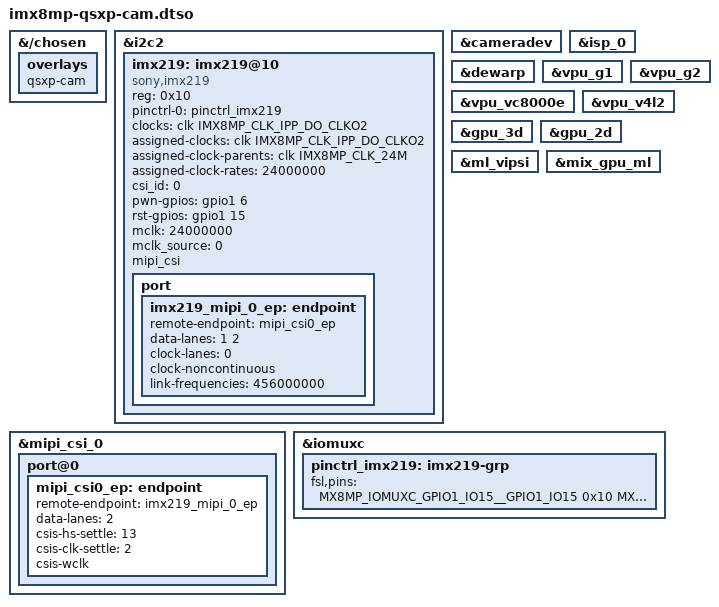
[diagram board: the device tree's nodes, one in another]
// SPDX-License-Identifier: (GPL-2.0 OR MIT)
/*
 * Copyright 2023 Markus Bauer <MB@KARO-electronics.de>
 *
 */

/dts-v1/;
/plugin/;

#include <dt-bindings/clock/imx8mp-clock.h>
#include <dt-bindings/gpio/gpio.h>
#include "imx8mp-pinfunc.h"

&{/chosen} {
	overlays {
		qsxp-cam;
	};
};

&i2c2 {
	imx219: imx219@10 {
		compatible = "sony,imx219";
		reg = <0x10>;
		pinctrl-names = "default";
		pinctrl-0 = <&pinctrl_imx219>;
		clocks = <&clk IMX8MP_CLK_IPP_DO_CLKO2>;
		clock-names = "xclk";
		assigned-clocks = <&clk IMX8MP_CLK_IPP_DO_CLKO2>;
		assigned-clock-parents = <&clk IMX8MP_CLK_24M>;
		assigned-clock-rates = <24000000>;
		csi_id = <0>;
		pwn-gpios = <&gpio1 6 GPIO_ACTIVE_HIGH>;
		rst-gpios = <&gpio1 15 GPIO_ACTIVE_HIGH>;
		mclk = <24000000>;
		mclk_source = <0>;
		mipi_csi;
		status = "okay";

		port {
			imx219_mipi_0_ep: endpoint {
				remote-endpoint = <&mipi_csi0_ep>;
				data-lanes = <1 2>;
				clock-lanes = <0>;
				clock-noncontinuous;
				link-frequencies = /bits/ 64 <456000000>;
			};
		};
	};
};

&cameradev {
	status = "okay";
};

&mipi_csi_0 {
	status = "okay" ;

	port@0 {
		mipi_csi0_ep: endpoint {
			remote-endpoint = <&imx219_mipi_0_ep>;
			data-lanes = <2>;
			csis-hs-settle = <13>;
			csis-clk-settle = <2>;
			csis-wclk;
		};
	};
};

&isp_0 {
	status = "okay";
};

&dewarp {
	status = "okay";
};

&vpu_g1 {
	status = "okay";
};

&vpu_g2 {
	status = "okay";
};

&vpu_vc8000e {
	status = "okay";
};

&vpu_v4l2 {
	status = "okay";
};

&gpu_3d {
	status = "okay";
};

&gpu_2d {
	status = "okay";
};

&ml_vipsi {
	status = "okay";
};

&mix_gpu_ml {
	status = "okay";
};

&iomuxc {
	pinctrl_imx219: imx219-grp {
		fsl,pins = <
			MX8MP_IOMUXC_GPIO1_IO15__GPIO1_IO15		0x10
			MX8MP_IOMUXC_GPIO1_IO06__GPIO1_IO06		0x10
		>;
	};
};
